# MCU_CPSW0_NUSS_ALE register map
Vendor: Texas Instruments
Peripheral module from a debugger description file (folder J7VCL).
Registers are 32-bit, read-write, reset values left out (the file's numbers can be read two ways) unless marked. A register's access mark holds for its fields unless they carry their own. Offsets are as the file gives them; lines under a group give offsets from that group; [hi:lo] are bit positions; {n}, {i} and the like mark numbered series; 'fields as' and 'values as' point back to an identical list; <NAME> marks a mode.

## MCU_CPSW0_NUSS_ALE
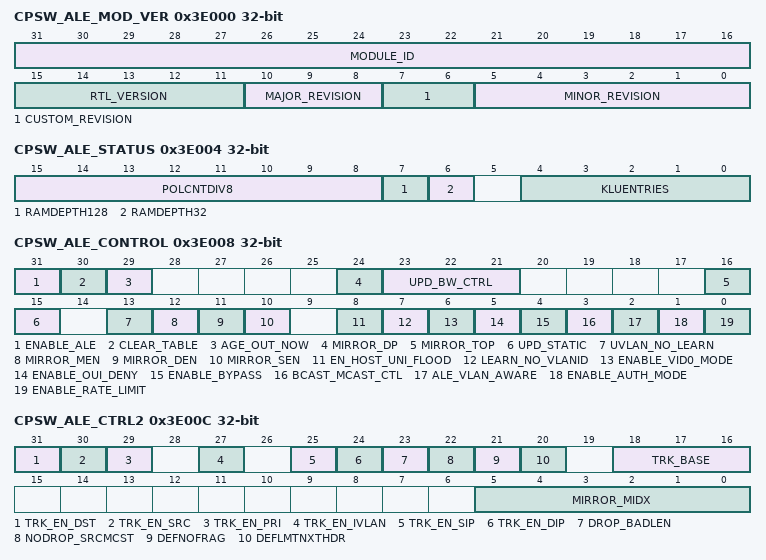
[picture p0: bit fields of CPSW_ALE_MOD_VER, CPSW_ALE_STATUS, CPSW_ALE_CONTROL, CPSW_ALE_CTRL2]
0x3E000 CPSW_ALE_MOD_VER ro — The Module and Version Register identifies the module identifier of the ALE_2g64i module.
  [31:16] MODULE_ID — ALE module ID.
  [15:11] RTL_VERSION
  [10:8] MAJOR_REVISION
  [7:6] CUSTOM_REVISION
  [5:0] MINOR_REVISION
0x3E004 CPSW_ALE_STATUS ro — The ALE status provides information on the ALE configuration and state. The RAMDEPTH is used to determine how IPv6 entries are stored in the table. IPv6 entries are stored in two entries where IPv6 Entry Hi is designated by the odd slice index and Lo is designated by the even slice index. The slice index is above the ram depth like {SlixeIndex,RamIndex}. So for a 64 deep RAM index of 0x005, the Hi portion of the IPv6 entry is located at 0x005|0x040 and the Lo portion is located at 0x005&(~0x040).
  [15:8] POLCNTDIV8 — This is the number of policer engines the ALE implements divided by 8.A value of 4 indicates 32 policer engines total.
  [7] RAMDEPTH128 — The number of ALE entries per slice of the table when this is set it indicates the depth is 128 if both RAMDEPTH128 and RAMDEPTH32 are zero the depth is 64.
  [6] RAMDEPTH32 — The number of ALE entries per slice of the table when this is set it indicates the depth is 32 if both RAMDEPTH128 and RAMDEPTH32 are zero the depth is 64.
  [4:0] KLUENTRIES — This is the number of table entries total divided by 1024.A value of 1h indicates 1024 table entries. A value of 8h indicates 8192 table entries.
0x3E008 CPSW_ALE_CONTROL — The ALE Control Register is used to set the ALE modes used for all ports.
  [31] ENABLE_ALE — Enable ALE.0h = Drop all packets 1h = Enable ALE packet processing
  [30] CLEAR_TABLE — Clear ALE address table. Setting this bit causes the ALE hardware to write all table bit values to zero.Software must perform a clear table operation as part of the ALE setup/configuration process. Setting this bit causes all ALE accesses to be held up for 64 clocks while the clear is performed. Access to all ALE registers will be blocked (wait states) until the 64 clocks have completed. This bit cannot be read as one because the read is blocked until the clear table is completed at which time this bit is cleared to zero.
  [29] AGE_OUT_NOW — Age Out Address Table Now. Setting this bit causes the ALE hardware to remove (free up) any ageable table entry that does not have a set touch bit.This bit is cleared when the age out process has completed. This bit may be read. The age out process takes four times the number of table entries clock cycles (4096 cycles for 1K addresses) best case (no ale packet processing during ageout) and sixty five times the number of table entries clock cycles (66560 cycles for 1K addresses) absolute worst case.
  [24] MIRROR_DP — Mirror Destination Port. This field defines the port to which destination traffic destined will be duplicated.That is all traffic that is forwarded to this port will also be mirrored to the MIRROR_TOP port.
  [23:21] UPD_BW_CTRL — The UPD_BW_CTRL field allows for up to 8 times the rate in which adds, updates, touches, writes, and aging updates can occur.At frequencies of 350Mhz, the table update rate should be at it lowest or 5 Million updates per second. When operating the switch core at frequencies or above, the UPD_BW_CTRL can be programmed more aggressive. If the UPD_BW_CTRL is set but the frequency of the switch subsystem is below the associated value, ALE will drop packets due to insufficient time to complete lookup under high traffic loads. 0h = 350Mhz, 5M 1h = 359Mhz, 11M 2h = 367Mhz, 16M 3h = 375Mhz, 22M 4h = 384Mhz, 28M 5h = 392Mhz, 34M 6h = 400Mhz, 39M 7h = 409Mhz, 45M
  [16] MIRROR_TOP — Mirror To Port. This field defines the destination port for the mirror traffic.If the traffic is received or transmitted on the mirror destination port it will not be duplicated. Traffic defined as mirror traffic only may be dropped by the switch due to congestion.
  [15] UPD_STATIC — Update Static Entries - A static Entry is an entry that is not agable.When clear this bit will prevent any static entry (agable bit clear) from being updated due to port change. When set it allows static entries (agable bit clear) to update the source port if required. This bit should normally be 0h for most switch configurations.
  [13] UVLAN_NO_LEARN — Unknown VLAN No Learn. This field when set will prevent source addresses of unknown VLAN IDs from being automatically added into the look up table if learning is enabled.
  [12] MIRROR_MEN — Mirror Match Entry Enable. This field enables the match mirror option.When this bit is set any traffic whose destination, source, VLAN or OUI matches the ~imirror_midx entry index will have that traffic also sent to the ~imirror_top port.
  [11] MIRROR_DEN — Mirror Destination Port Enable - This field enables the destination port mirror option.When this bit is set any traffic destined for the ~imirror_dp port will have its transmit traffic also sent to the ~imirror_top port.
  [10] MIRROR_SEN — Mirror Source Port Enable - This field enables the source port mirror option.When this bit is set any port with the Iy_REG_P0_MIRROR_SP set in the CPSW_Iy_ALE_PORTCTL0_y registers set will have its received traffic also sent to the MIRROR_TOP port.
  [8] EN_HOST_UNI_FLOOD — Unknown unicast packets flood to host.0h = Unknown unicast packets are not sent to the host.1h = Unknown unicast packets flood to host port as well as other ports.
  [7] LEARN_NO_VLANID — Learn No VID.0h = VID is learned with the source address.1h = VID is not learned with the source address (source address is not tied to VID). Determines the entry type.
  [6] ENABLE_VID0_MODE — Enable VLAN ID = 0 Mode0h = Process the priority tagged packet with VID = PORT_VLAN[11:0]. 1h = Process the priority tagged packet with VID = 0h.
  [5] ENABLE_OUI_DENY — Enable OUI Deny Mode.0h = Any packet source address matching an OUI address table entry will be dropped to the host unless the destination address matches with a supervisory destination address table entry.1h = Any packet with a non-matching OUI source address will be dropped to the host unless the packet destination address matches a supervisory destination address table entry.
  [4] ENABLE_BYPASS — ALE Bypass. When set, packets received on non-host ports are sent to the host.It is expected that packets from the host are directed to the particular port. 0h = No bypass 1h = Bypass the ALE
  [3] BCAST_MCAST_CTL — Rate Limit Transmit mode.0h = Broadcast and multicast rate limit counters are received port based.1h = Broadcast and multicast rate limit counters are transmit port based.
  [2] ALE_VLAN_AWARE — ALE VLAN Aware. Determines how traffic is forwarded using VLAN rules.0h = Simple switch rules, packets forwarded to all ports for unknown destinations. 1h = VLAN Aware rules, packets forwarded based on VLAN members
  [1] ENABLE_AUTH_MODE — Enable MAC Authorization Mode. Mac authorization mode requires that all table entries be made by the host software.There is no auto learning of addresses in authorization mode and the packet will be dropped if the source address is not found (and the destination address is not a multicast address with the super table entry bit set). 0h = The ALE is not in MAC authorization mode 1h = The ALE is in MAC authorization mode
  [0] ENABLE_RATE_LIMIT — Enable Broadcast and Multicast Rate Limit0h = Broadcast/Multicast rates not limited 1h = Broadcast/Multicast packet reception limited to the port control register rate limit fields.
0x3E00C CPSW_ALE_CTRL2 — The ALE Control 2 Register is used to set the extended features used for all ports.
  [31] TRK_EN_DST — Trunk Enable Destination Address.This field enables the destination MAC address to be used with the hash function G(X) = 1 + X + X^3 and affect the trunk port transmit link determination.
  [30] TRK_EN_SRC — Trunk Enable Source Address.This field enables the source MAC address to be used with the hash function G(X) = 1 + X + X^3 and affect the trunk port transmit link determination.
  [29] TRK_EN_PRI — Trunk Enable Priority.This field enables the VLAN Priority bits to be used with the hash function G(X) = 1 + X + X^3 and affect the trunk port transmit link determination. In the event that DSCP mapping is enabled and there is no VLAN the DSCP priority will be used. For all other non IP frames without VLAN the port default priority is used.
  [27] TRK_EN_IVLAN — Trunk Enable Inner VLAN.This field enables the inner VLAN ID value (C-VLANID) to be used with the hash function G(X) = 1 + X + X^3 and affect the trunk port transmit link determination.
  [25] TRK_EN_SIP — Trunk Enable Source IP Address.This field enables the source IP address to be used with the hash function G(X) = 1 + X + X^3 and affect the trunk port transmit link determination. This feature supports No tag, Priority tagged, VLAN tagged, Q-in-Q double tagging for both IPV6 and IPV4.
  [24] TRK_EN_DIP — Trunk Enable Destination IP Address.This field enables the destination IP address to be used with the hash function G(X) = 1 + X + X^3 and affect the trunk port transmit link determination. This feature supports No tag, Priority tagged, VLAN tagged, Q-in-Q double tagging for both IPV6 and IPV4.
  [23] DROP_BADLEN — Drop Bad Length will drop any packet that the 802.3 length field is larger than the packet.Ethertypes 0-1500 are 802.3 lengths, all others are Ether types.
  [22] NODROP_SRCMCST — No Drop Source Multicast will disable the dropping of any source address with the multicast bit set.
  [21] DEFNOFRAG — Default No Frag field will cause an IPv4 fragmented packet to be dropped if a VLAN entry is not found.
  [20] DEFLMTNXTHDR — Default limit next header field will cause an IPv4 protocol or IPv6 next header packet to be dropped if a VLAN entry is not found and the protocol or next header does not match theCPSW_ALE_NXT_HDR register values.
  [18:16] TRK_BASE — Trunk Base. This field is the hash formula starting value.Changing this value will cause the packet distribution on trunk ports to be changed. If all the [31]TRK_EN_DST, [30]TRK_EN_SRC, [29]TRK_EN_PRI and [27]TRK_EN_VLAN bits are cleared (value: 0h), this value is used as the distribution index. That is a 0h will select the 1st bit of an 'N' link trunk, a 1h will select the second, etc. Below is the distribution across the trunk links. The first number in the sequence indicates the traffic is sent to the lowest numbered port of a trunk group. For example if you have a 3 port trunk, the hash result 0h will go to the base port (0), hash result 1h will go to the highest port of the trunk group (2), hash result 2h will go to the middle port (1), etc. 1h = 00000000 2h = 01010101 3h = 02102102 4h = 03210321
  [5:0] MIRROR_MIDX — Mirror Index. This field is the ALE lookup table entry index that when a match occurs will cause this traffic to be mirrored to the MIRROR_TOP port.That is any VLAN, ONU or address with or withou VLAN can be selected for traffic mirroring.
0x3E010 CPSW_ALE_PRESCALE — The ALE Prescale Register is used to set the Broadcast and Multicast rate limiting prescaler value.
  [19:0] ALE_PRESCALE — ALE Prescale. The input clock is divided by this value for use in the multicast/broadcast rate limiters.The minimum operating value is 10h. The prescaler is off when the value is zero.
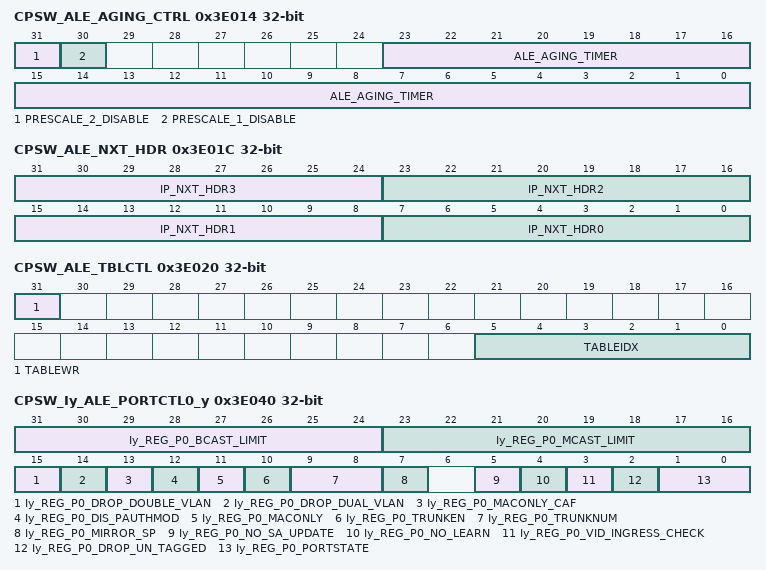
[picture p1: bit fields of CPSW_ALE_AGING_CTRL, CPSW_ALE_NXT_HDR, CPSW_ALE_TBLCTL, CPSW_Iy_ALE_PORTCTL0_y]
0x3E014 CPSW_ALE_AGING_CTRL — The ALE Aging Control sets the aging interval which will cause periodic aging to occur. This value specifies the minimum time between aging starts.
  [31] PRESCALE_2_DISABLE — ALE Prescaler 2 Disable.When set will divide the aging interval by 1000. This bit is designed for device verification and should not be used in production software. Combination of PreScale1Disable and PreScale2Disable will divide the aging interval by 1,000,000 for test purposes.
  [30] PRESCALE_1_DISABLE — ALE Prescaler 1 Disable. When set will divide the aging interval by 1000. This bit is designed for device verification and should not be used in production software. Combination of PreScale1Disable and PreScale2Disable will divide the aging interval by 1,000,000 for test purposes.
  [23:0] ALE_AGING_TIMER
0x3E01C CPSW_ALE_NXT_HDR — The ALE Next Header is used to limit the IPv6 Next header or IPv4 Protocol values found in the IP header. It is enabled via the DEFLMTNXTHDR bit in the VLAN entry. All four IP_NXT_HDR0 to IP_NXT_HDR3 bits are compared when enabled, so if only one is required, set them all to the one value to be tested.
  [31:24] IP_NXT_HDR3 — The IP_NXT_HDR3 is the forth protocol or next header compared when enabled.
  [23:16] IP_NXT_HDR2 — The IP_NXT_HDR2 is the third protocol or next header compared when enabled.
  [15:8] IP_NXT_HDR1 — The IP_NXT_HDR1 is the second protocol or next header compared when enabled.
  [7:0] IP_NXT_HDR0 — The IP_NXT_HDR0 is the first protocol or next header compared when enabled.
0x3E020 CPSW_ALE_TBLCTL — The ALE table control register is used to read or write that ALE table entries. After writing to this register any read or write to any ALE register will be stalled until the read or write operation completes.
  [31] TABLEWR — Table Write. This bit is used to write the table words to the lookup table.0h = Table Read Operation is performed. The contents of the TABLEIDX bit will be read into the CPSW_ALE_TBLWx registers (where x = 0 to 2).1h = Table write operation is performed. This will take the current contents from the CPSW_ALE_TBLWx registers and write them to the table at the specified TABLEIDX.
  [5:0] TABLEIDX — The table index is used to determine which lookup table entry is read or written.
0x3E034 CPSW_ALE_TBLW2 — The ALE Table Word 2 is the most significant word of an ALE table entry.
  [6:0] TABLEWRD2 — Table Entry bits [71-64]
0x3E038 CPSW_ALE_TBLW1 — The ALE Table Word 1 is the middle word of an ALE table entry.
  [31:0] TABLEWRD1 — Table Entry bits [63-32]
0x3E03C CPSW_ALE_TBLW0 — The ALE Table Word 0 is the least significant word of an ALE table entry.
  [31:0] TABLEWRD0 — Table Entry bits [31-0]
0x3E040 CPSW_Iy_ALE_PORTCTL0_y — The ALE Port Control Register sets the port specific modes of operation. Offset = 0003E040h + (y * 4h); where y = 0 to 1
  [31:24] Iy_REG_P0_BCAST_LIMIT — Broadcast Packet Rate Limit - Each prescale pulse loads this field into the port broadcast rate limit counter.The port counters are decremented with each packet received or transmitted depending on whether the mode is transmit or receive. If the counters decrement to zero, then further packets are rate limited until the next prescale pulse. Broadcast rate limiting is enabled by a non-zero value in this field.
  [23:16] Iy_REG_P0_MCAST_LIMIT — Multicast Packet Rate Limit - Each prescale pulse loads this field into the port multicast rate limit counter.The port counters are decremented with each packet received or transmitted depending on whether the mode is transmit or receive. If the counters decrement to zero, then further packets are rate limited until the next prescale pulse. Multicast rate limiting is enabled by a non-zero value in this field.The Iy_REG_P0_MCAST_LIMIT bit field is the number of Multicast packets that will be forwaded per CPSW_ALE_PRESCALE time.
  [15] Iy_REG_P0_DROP_DOUBLE_VLAN — Drop Double VLAN.When set cause any received packet with double VLANs to be dropped. That is if there are two ctag or two stag fields in the packet it will be dropped.
  [14] Iy_REG_P0_DROP_DUAL_VLAN — Drop Dual VLAN. When set will cause any received packet with dual VLAN stag followed by ctag to be dropped.
  [13] Iy_REG_P0_MACONLY_CAF — Mac Only Copy All Frames.When set a Mac Only port will transfer all received good frames to the host. When clear a Mac Only port will transfer packets to the host based on ALE destination address lookup operation (which operates more like an Ethernet Mac). A Mac Only port is a port with Iy_REG_P0_MACONLY set.
  [12] Iy_REG_P0_DIS_PAUTHMOD — Disable Port authorization. When set will allow unknown addresses to arrive on a switch in authorization mode. It is intended for device to device network connection on ports which do not require MACSEC encryption.
  [11] Iy_REG_P0_MACONLY — MAC Only.When set enables this port be treated like a MAC port for the host. All traffic received is only sent to the host. The host must direct traffic to this port as the lookup engine will not send traffic to the ports with the Iy_REG_P0_MACONLY bit set and the Iy_REG_P0_NO_LEARN also set. If Iy_REG_P0_MACONLY bit is set and the Iy_REG_P0_NO_LEARN is not set, the host can send non-directed packets that can be sent to the destination of a MacOnly port. It is also possible that the host can broadcast to all ports including MacOnly ports in this mode.
  [10] Iy_REG_P0_TRUNKEN — Trunk Enable. This field is used to enable a port into a trunk.Any port can be used as a trunk port, any two or more ports with the Iy_REG_P0_TRUNKEN bit is set and having the same Iy_REG_P0_TRUNKNUM will be placed in the same trunk. There is no requirement for trunk ports to be adjacent. If all ports are enabled in the same trunk, no traffic can flow as traffic received within a trunk is never trasnmitted out the same trunk. If only a single port is a member of a trunk, it looks like a normal port with exception of entries in the look up table will be noted as a trunk entry.
  [9:8] Iy_REG_P0_TRUNKNUM — Trunk Number. This field is used as the trunk number when the Iy_REG_P0_TRUNKEN bit is also set.Ports with the same trunk number that have the Iy_REG_P0_TRUNKEN bit is also set will have traffic distributed within the trunk based on the result of the hash function descrived above.
  [7] Iy_REG_P0_MIRROR_SP — Mirror Source Port - This field enables the source port mirror option.When this bit is set any traffic received on the port with the Iy_REG_P0_MIRROR_SP bit set will have its received traffic also sent to the MIRROR_TOP port.
  [5] Iy_REG_P0_NO_SA_UPDATE — No Source Address Update.When set will not update the source addresses for this port.
  [4] Iy_REG_P0_NO_LEARN — No Learn.When set will not learn the source addresses for this port.
  [3] Iy_REG_P0_VID_INGRESS_CHECK — VLAN Ingress Check.When set if a packet received is not a member of the VLAN, the packet will be dropped.
  [2] Iy_REG_P0_DROP_UN_TAGGED — If Drop Untagged. When set will drop packets without a VLAN tag.
  [1:0] Iy_REG_P0_PORTSTATE — Port State. Defins the current port state used for lookup operations.0h = Disabled 1h = Blocked 2h = Learning 3h = Forwarding
0x3E090 CPSW_ALE_UVLAN_MEMBER — The ALE Unknown VLAN Member Mask Register is used to specify the member list for unknown VLAN ID.
  [1:0] UVLAN_MEMBER_LIST — Unknown VLAN Member List.
0x3E094 CPSW_ALE_UVLAN_URCAST — The ALE Unknown VLAN Unregistered Multicast Flood Mask Register is used to specify which egress ports unregistered multicast addresses egress for the unregistered VLAN ID.
  [1:0] UVLAN_UNREG_MCAST_FLOOD_MASK — Unknown VLAN Unregister Multicast Flood Mask.
0x3E098 CPSW_ALE_UVLAN_RMCAST — The ALE Unknown VLAN Registered Multicast Flood Mask Register is used to specify which egress ports registered multicast addresses egress for the unregistered VLAN ID.
  [1:0] UVLAN_REG_MCAST_FLOOD_MASK — Unknown VLAN Register Multicast Flood Mask.
0x3E09C CPSW_ALE_UVLAN_UNTAG — The ALE Unknown VLAN force Untagged Egress Mask Register is used to specify which egress ports the VLAN ID will be removed.
  [1:0] UVLAN_FORCE_UNTAGGED_EGRESS — Unknown VLAN Force Untagged Egress Mask.
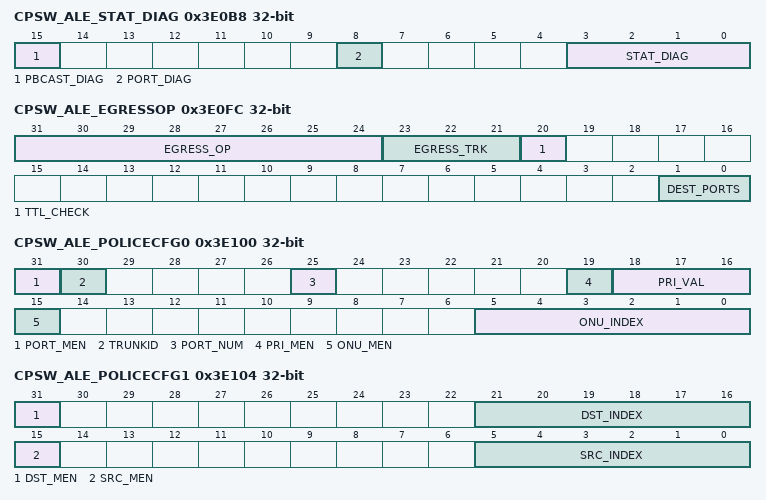
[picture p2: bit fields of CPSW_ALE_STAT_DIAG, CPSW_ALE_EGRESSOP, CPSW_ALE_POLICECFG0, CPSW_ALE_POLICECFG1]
0x3E0B8 CPSW_ALE_STAT_DIAG — The ALE Statistic Output Diagnostic Register allows the output statistics to diagnose the SW counters. This register is for diagnostic only.
  [15] PBCAST_DIAG — When set and the PORT_DIAG is set to zero, will allow all ports to see the same stat diagnostic increment.
  [8] PORT_DIAG — The port selected that a received packet will cause the selected error to increment
  [3:0] STAT_DIAG — When non-zero will cause the selected statistic to increment on the next frame received.For the selected Port. 0h = Disabled 1h = Destination Equal Source Drop Stat will count 2h = VLAN Ingress Check Drop Stat will count 3h = Source Multicast Drop Stat will count 4h = Dual VLAN Drop Stat will count 5h = Ether Type length error Drop Stat will count 6h = Next Hop Limit Drop Stat will count 7h = IPv4 Fragment Drop Stat will count 8h = Classifier Hit Stat will count 9h = Classifier Red Drop Stat will count 10h = Classifier Yellow Drop Stat will count 11h = ALE Overflow Drop Stat will count 12h = Rate Limit Drop Stat will count 13h = Blocked Address Drop Stat will count 14h = Secure Address Drop Stat will count 15h = Authorization Drop Stat will count
0x3E0BC CPSW_ALE_OAM_LB_CTRL — The ALE OAM Control allows ports to be put into OAM Loopback, only non-supervisor packet are looped back to the source port.
  [1:0] OAM_LB_CTRL — The OAM_LB_CTRL bit field allows any port to be put into OAM loopback, that is any packet received will be returned to the same port with anCPSW_ALE_EGRESSOP[31-24] EGRESS_OP of 0xFF which swaps the source (SA) and destination address (DA). BPDUs will still flow through as normal so that OAM can be remotly requested and disabled.
0x3E0C0 CPSW_ALE_MSK_MUX0 ro — VLAN Mask Mux 0. The ALE Mask Mux 0 register is used along with the VLAN registered/unregistered index selectors from the Lookup Table to determine the value for VLAN registered and unregister mask respectively.
  [1:0] VLAN_MASK_MUX_0
0x3E0C4 CPSW_Ix_ALE_MSK_MUXx — VLAN Mask Mux x (where x = 1 to 3). The ALE Mask Mux registers are used along with the VLAN registered/unregistered index selectors from the Lookup Table to determine the value for VLAN registered and unregister mask respectively. Offset = 0003E0C4h + (x * 4h); where x = 1 to 3
  [1:0] Ix_REG_VLAN_MASK_MUX_x — VLAN Mask Mux x (where x = 1 to 3).
0x3E0FC CPSW_ALE_EGRESSOP — The Egress Operation register allows enabled classifiers with IPSA or IPDA match to use the CPSW Egress Packet Operations Inter VLAN Routing sub functions. If the packet was destined for the host, but matches a clasifier that has a programmed egress opcode, it will be forwarded to the destination ports where the destination ports will use the thier egress opcode entry to modify the packet. InterVLAN Routing and mirroring need to be understood, they are orthogonal functions.
  [31:24] EGRESS_OP — The Egress Operation defines the operation performed by the CPSW Egress Packet Operations0h = NOP : 1-n: Defines which egress Operation will be performed. This allows Inter VLAN routing to be configured for high bandwidth traffic, reducing CPU load. FFh: Swaps source address (SA) and destination address (DA) of packet, this is intended to allow OAM diagnostics for a link.
  [23:21] EGRESS_TRK — The Egress Trunk Index is the calculated trunk index from the SA, DA or VLAN if modified to that InterVLAN routing will work on trunks as well.The DA, SA and VLAN are ignored for trunk generation on InterVLAN Routing so that this field is the index generated from the Egress Op replacements elclusive or'd together into a three bit index.
  [20] TTL_CHECK — The TTL Check will cause any packet that fails TTL checks to not be routed to the Inter VLAN Routing sub functions.The packet will be routed to the host it was destined to.
  [1:0] DEST_PORTS — The Destination Ports is a list of the ports the classified packet will be set to.If a destination is a Trunk, all the port bits for that trunck must be set.
0x3E100 CPSW_ALE_POLICECFG0 — The Policing Config 0 holds the port, frame priority and ONU address index as well as match enables for port, frame priority and ONU address matching.
  [31] PORT_MEN — Port Match Enable.
  [30] TRUNKID
  [25] PORT_NUM — Port Number.
  [19] PRI_MEN — Priority Match Enable.
  [18:16] PRI_VAL — Priority Value.
  [15] ONU_MEN — OUI Match Enable.
  [5:0] ONU_INDEX — OUI Table Entry Index.
0x3E104 CPSW_ALE_POLICECFG1 — The Policing Config 1 holds the match enable/match index for the L2 Destination and L2 source addresses.
  [31] DST_MEN — Destination Address Match Enable.
  [21:16] DST_INDEX — Destination Address Table Entry Index.
  [15] SRC_MEN — Source Address Match Enable.
  [5:0] SRC_INDEX — Source Address Table Entry Index.
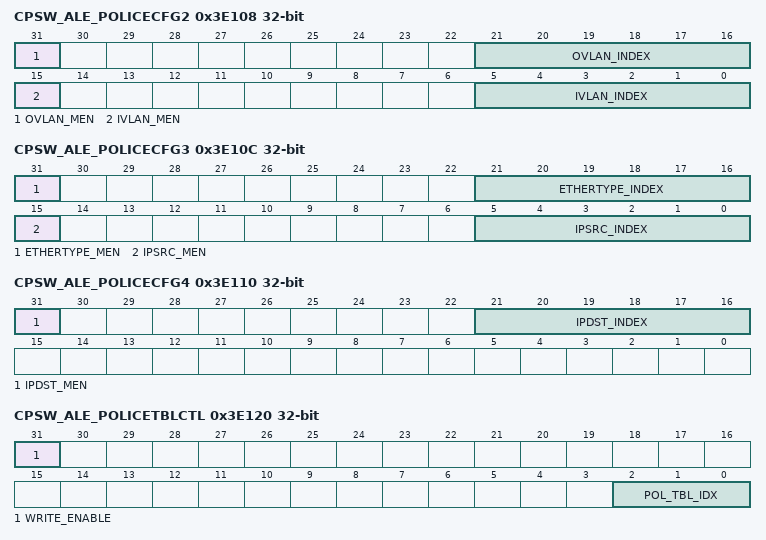
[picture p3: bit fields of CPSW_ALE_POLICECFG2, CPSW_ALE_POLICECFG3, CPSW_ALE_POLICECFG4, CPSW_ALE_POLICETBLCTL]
0x3E108 CPSW_ALE_POLICECFG2 — The Policing Config 2 holds the match enable/match index for the Outer VLAN and Inner VLAN addresses.
  [31] OVLAN_MEN — Outer VLAN Match Enable.
  [21:16] OVLAN_INDEX — Outer VLAN Table Entry Index.
  [15] IVLAN_MEN — Inner VLAN Match Enable.
  [5:0] IVLAN_INDEX — Inner VLAN Table Entry Index.
0x3E10C CPSW_ALE_POLICECFG3 — The Policing Config 3 holds the match enable/match index for the Ether Type and IP Source address.
  [31] ETHERTYPE_MEN — EtherType Match Enable.
  [21:16] ETHERTYPE_INDEX — EtherType Table Entry Index.
  [15] IPSRC_MEN — IP Source Address Match Enable.
  [5:0] IPSRC_INDEX — IP Source Address Table Entry Index.
0x3E110 CPSW_ALE_POLICECFG4 — The Policing Config 4 holds the match enable/match index for the IP Destination address
  [31] IPDST_MEN — IP Destination Address Match Enable.
  [21:16] IPDST_INDEX — IP Destination Address Table Entry Index.
0x3E118 CPSW_ALE_POLICECFG6 — The PIR counter is a 37 bit internal counter where PIR_IDLE_INC_VAL is added every clock and the frame size << 18 is subtracted at EOF if not RED at LUT time. If the counter is negative the packet will be marked RED, else it can be YELLOW or GREEN based on the CIR counter. If only this counter is used (CIR_IDLE_INC_VAL = 0h), then packets are marked RED or GREEN based on PIR counter only.
  [31:0] PIR_IDLE_INC_VAL — Peak Information Rate Idle Increment Value.
0x3E11C CPSW_ALE_POLICECFG7 — The CIR counter is a 37 bit internal counter where CIR_IDLE_INC_VAL is added every clock and the frame size << 18 is subtracted at EOF if not RED or YELLOW at LUT time. If the counter is positive the packet will be marked GREEN, else it can be YELLOW or RED based on the PIR counter. If only this counter is used (PIR_IDLE_INC_VAL= 0h), then packets are marked YELLOW or GREEN based on CIR counter only.
  [31:0] CIR_IDLE_INC_VAL — Committed Information Idle Increment Value - The number added to the CIR counter every clock cycle.If zero the CIR counter is disabled and packets will never be marked or processed as YELLOW.
0x3E120 CPSW_ALE_POLICETBLCTL — The Policing Table Control is used to read or write the selected policing/classifier entry. The selected policing/classifier entry is only read or written after this register is written based on the value of the WRITE_ENABLE bit.
  [31] WRITE_ENABLE
  [2:0] POL_TBL_IDX — Policer Entry Index.
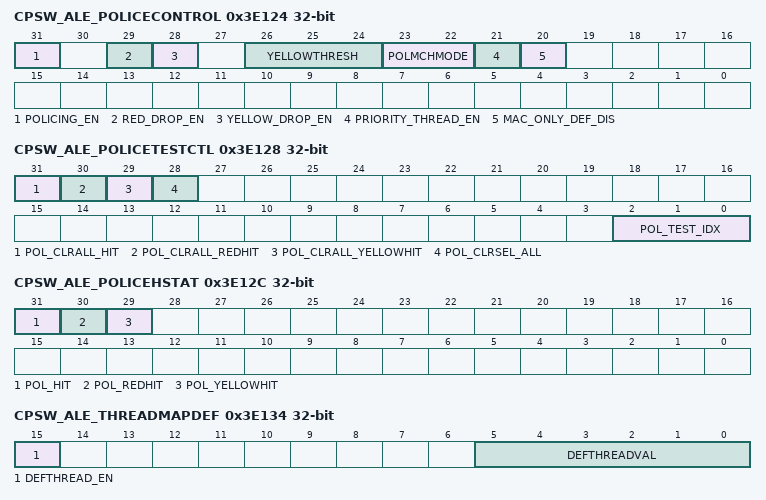
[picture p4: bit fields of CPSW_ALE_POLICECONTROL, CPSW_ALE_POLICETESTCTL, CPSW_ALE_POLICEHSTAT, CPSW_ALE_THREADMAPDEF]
0x3E124 CPSW_ALE_POLICECONTROL — The Control Enables color marking as well as internal ALE packet dropping rules.
  [31] POLICING_EN — Policing Enable - Enables the policing to color the packets, this also enables red or yellow drop capabilities.
  [29] RED_DROP_EN — RED Drop Enable - Enables the ALE to drop the red colored packets.
  [28] YELLOW_DROP_EN — WELLOW Drop Enable - Enables the ALE to drop yellow packets based on the YELLOWTHRESH bit value.This field would normally not be used as to let the switch drop packets at a buffer threshold instead. In the event that the switch does not enable buffer threshold dropping, YELLOW packets can be dropped based on this feature.
  [26:24] YELLOWTHRESH — Yellow Threshold - When set enables a portion of the yellow packets to be dropped based on the YELLOW_DROP_EN bit enable.0h = 100% 1h =50% 2h = 33% 3h = 25% 4h = 20% 5h = 17% 6h = 14% 7h = 13%
  [23:22] POLMCHMODE — Policing Match Mode - This field determines what happens to packets that fail to hit any policing/classifier entry.0h = No Hit packets are marked GREEN 1h = No Hit packets are marked YELLOW 2h = No Hit packets are marked RED 3h = No Hit packets are marked based on policing/classifier entry=0 state.
  [21] PRIORITY_THREAD_EN — Priority Thread Enable - This field determines if priority is OR'd to the default thread when no classifiers hit and the default thread is enabled.
  [20] MAC_ONLY_DEF_DIS — MAC Only Default Disable - This field when set disables the default thread on MAC Only Ports.That is the default thread will be {port,priority}. If the traffic matches a classifier with a thread mapping, the classifier thread mapping still occurs.
0x3E128 CPSW_ALE_POLICETESTCTL — The Policing Test Control enables the ability to determine which policing entry has been hit and whether they reported a red or yellow rate condition.
  [31] POL_CLRALL_HIT — Policer Clear - This bit clears all the policing/classifier hit bits.This bit is self clearing. This can be used to test the fact that a policing/classifier entry has been hit.
  [30] POL_CLRALL_REDHIT — Policer Clear RED - This bit clears all the policing/classifier RED hit bits.This bit is self clearing. This can be used to test the fact that a policing/classifier entry has been hit during a RED condition.
  [29] POL_CLRALL_YELLOWHIT — Policer Clear YELLOW - This bit clears all the policing/classifier YELLOW hit bits.This bit is self clearing. This can be used to test the fact that a policing/classifier entry has been hit during a YELLOW condition.
  [28] POL_CLRSEL_ALL — Police Clear Selected - This bit clears the selected policing/classifier hit, redhit and yellowhit bits.This bit is self clearing.
  [2:0] POL_TEST_IDX — Policer Test Index - This field selects which policing/classifier hit bits will be read or written.
0x3E12C CPSW_ALE_POLICEHSTAT ro — The policing hit status is a read only register that reads the hit bits of the selected policing/classifier.
  [31] POL_HIT — Policer Hit.
  [30] POL_REDHIT — Policer Hit RED.
  [29] POL_YELLOWHIT — Policer Hit YELLOW.
0x3E134 CPSW_ALE_THREADMAPDEF — The THREAD Mapping Default Value register is used to set the default thread ID when no classifier is matched.
  [15] DEFTHREAD_EN — Default Tread Enable.
  [5:0] DEFTHREADVAL — Default Thread Value.
0x3E138 CPSW_ALE_THREADMAPCTL — The THREAD Mapping Control register allows the highest matched classifier to return a particular thread ID for traffic sent to the host. This allows particular classifier matched traffic to be placed an a particular hosts queue.
  [2:0] CLASSINDEX — Classifier Index.
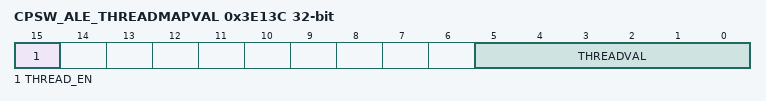
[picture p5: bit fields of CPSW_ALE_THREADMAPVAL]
0x3E13C CPSW_ALE_THREADMAPVAL — The THREAD Mapping Value register is used to set the thread ID for a particular classifier entry.
  [15] THREAD_EN — Thread Enable.
  [5:0] THREADVAL — Thread Value.
